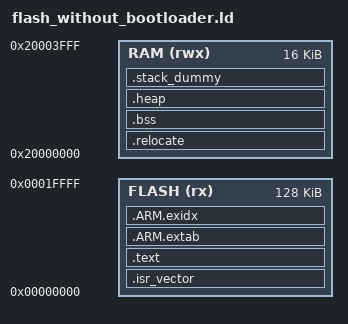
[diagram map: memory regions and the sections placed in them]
/*
  Copyright (c) 2014-2015 Arduino LLC.  All right reserved.

  This library is free software; you can redistribute it and/or
  modify it under the terms of the GNU Lesser General Public
  License as published by the Free Software Foundation; either
  version 2.1 of the License, or (at your option) any later version.

  This library is distributed in the hope that it will be useful,
  but WITHOUT ANY WARRANTY; without even the implied warranty of
  MERCHANTABILITY or FITNESS FOR A PARTICULAR PURPOSE.
  See the GNU Lesser General Public License for more details.

  You should have received a copy of the GNU Lesser General Public
  License along with this library; if not, write to the Free Software
  Foundation, Inc., 51 Franklin St, Fifth Floor, Boston, MA  02110-1301  USA
*/

/* Linker script for SAMD21G17D - 128KB Flash, 16KB RAM */
MEMORY
{
  FLASH (rx) : ORIGIN = 0x00000000, LENGTH = 0x00020000
  RAM (rwx) : ORIGIN = 0x20000000, LENGTH = 0x00004000
}

/* Linker script to place sections and symbol values. Should be used together
 * with other linker script that defines memory regions FLASH and RAM.
 * It references following symbols, which must be defined in code:
 *   Reset_Handler : Entry of reset handler
 *
 * It defines following symbols, which code can use without definition:
 *   __exidx_start
 *   __exidx_end
 *   __copy_table_start__
 *   __copy_table_end__
 *   __zero_table_start__
 *   __zero_table_end__
 *   __etext
 *   __data_start__
 *   __preinit_array_start
 *   __preinit_array_end
 *   __init_array_start
 *   __init_array_end
 *   __fini_array_start
 *   __fini_array_end
 *   __data_end__
 *   __bss_start__
 *   __bss_end__
 *   __end__
 *   end
 *   __HeapLimit
 *   __StackLimit
 *   __StackTop
 *   __stack
 */
ENTRY(Reset_Handler)

SECTIONS
{
	.isr_vector :
	{
		__isr_vector_start = .;
		KEEP(*(.isr_vector))
		__isr_vector_end = .;
	} > FLASH

	.text :
	{
		__text_start__ = .;

		KEEP(*(.init))
		KEEP(*(.fini))

		*(.text*)

		/* .ctors */
		*crtbegin.o(.ctors)
		*crtbegin?.o(.ctors)
		*(EXCLUDE_FILE(*crtend?.o *crtend.o) .ctors)
		*(SORT(.ctors.*))
		*(.ctors)

		/* .dtors */
 		*crtbegin.o(.dtors)
 		*crtbegin?.o(.dtors)
 		*(EXCLUDE_FILE(*crtend?.o *crtend.o) .dtors)
 		*(SORT(.dtors.*))
 		*(.dtors)

		*(.rodata*)

		KEEP(*(.eh_frame*))
	} > FLASH

	.ARM.extab :
	{
		*(.ARM.extab* .gnu.linkonce.armextab.*)
	} > FLASH

	__exidx_start = .;
	.ARM.exidx :
	{
		*(.ARM.exidx* .gnu.linkonce.armexidx.*)
	} > FLASH
	__exidx_end = .;

	__etext = .;

	.relocate : AT (__etext)
	{
		__data_start__ = .;
		*(.ramfunc .ramfunc.*);
		*(.data .data.*);

		. = ALIGN(4);
		/* preinit data */
		PROVIDE_HIDDEN (__preinit_array_start = .);
		KEEP(*(.preinit_array))
		PROVIDE_HIDDEN (__preinit_array_end = .);

		. = ALIGN(4);
		/* init data */
		PROVIDE_HIDDEN (__init_array_start = .);
		KEEP(*(SORT(.init_array.*)))
		KEEP(*(.init_array))
		PROVIDE_HIDDEN (__init_array_end = .);

		. = ALIGN(4);
		/* finit data */
		PROVIDE_HIDDEN (__fini_array_start = .);
		KEEP(*(SORT(.fini_array.*)))
		KEEP(*(.fini_array))
		PROVIDE_HIDDEN (__fini_array_end = .);

		KEEP(*(.jcr*))
		. = ALIGN(4);
		__data_end__ = .;

	} > RAM

	.bss :
	{
		. = ALIGN(4);
		__bss_start__ = .;
		*(.bss .bss.*)
		*(COMMON)
		. = ALIGN(4);
		__bss_end__ = .;
	} > RAM

	.heap (COPY):
	{
		__end__ = .;
		PROVIDE(end = .);
		*(.heap*)
		__HeapLimit = .;
	} > RAM

	/* .stack_dummy section doesn't contains any symbols. It is only
	 * used for linker to calculate size of stack sections, and assign
	 * values to stack symbols later */
	.stack_dummy (COPY):
	{
		*(.stack*)
	} > RAM

	/* Set stack top to end of RAM, and stack limit move down by
	 * size of stack_dummy section */
	__StackTop = ORIGIN(RAM) + LENGTH(RAM);
	__StackLimit = __StackTop - SIZEOF(.stack_dummy);
	PROVIDE(__stack = __StackTop);

	/* Check if data + heap + stack exceeds RAM limit */
	ASSERT(__StackLimit >= __HeapLimit, "region RAM overflowed with stack")
}
